AUTOSAR XML (schema 00050)
package /Pkg_ErrorMgrAgg_1_0_QM/ComponentTypes
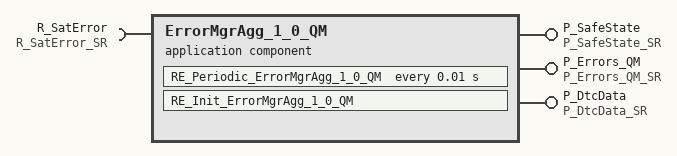
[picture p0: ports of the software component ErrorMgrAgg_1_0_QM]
  application sw component type ErrorMgrAgg_1_0_QM
    provide port P_SafeState: nonqueued-sender-com-spec{data-element=SafeStateOp, init-value=constant-reference=init_SafeStateOp}, provided-interface=P_SafeState_SR
    provide port P_Errors_QM: nonqueued-sender-com-spec=Errors_QM, provided-interface=P_Errors_QM_SR
    require port R_SatError: required-interface=R_SatError_SR
      required-com-specs:
        data-element=Data_ErrorMgr_ErrorCommPack_1_0_QM, init-value=constant-reference=init_Data_ErrorMgr_ErrorCommPack_1_0_QM
        data-element=Data_ErrorMgr_ErrorCommPack_2_0_QM, init-value=constant-reference=init_Data_ErrorMgr_ErrorCommPack_2_0_QM
        data-element=Data_ErrorMgr_ErrorCommPack_2_1_QM, init-value=constant-reference=init_Data_ErrorMgr_ErrorCommPack_2_1_QM
        data-element=Data_ErrorMgr_ErrorCommPack_QNX_QM, init-value=constant-reference=init_Data_ErrorMgr_ErrorCommPack_QNX_QM
    provide port P_DtcData: provided-interface=P_DtcData_SR
      provided-com-specs:
        data-element=Data_DtcStatus_QM, init-value=constant-reference=init_Data_DtcStatus_QM
        data-element=Data_DtcAddData_QM, init-value=constant-reference=init_Data_DtcAddData_QM
    behavior ErrorMgrAgg_1_0_QM_InternalBehavior: handle-termination-and-restart=NO-SUPPORT
      timing event TMT_RE_Periodic_ErrorMgrAgg_1_0_QM: start-on-event=RE_Periodic_ErrorMgrAgg_1_0_QM, period=0.01
      init event InitEvent: start-on-event=RE_Init_ErrorMgrAgg_1_0_QM
      port-api-options:
        enable-take-address=false, indirect-api=false, port=P_Errors_QM
        enable-take-address=false, indirect-api=false, port=P_SafeState
        enable-take-address=false, indirect-api=false, port=R_SatError
        enable-take-address=false, indirect-api=false, port=P_DtcData
      runnable RE_Periodic_ErrorMgrAgg_1_0_QM  # Periodic Runnable of Satellite
        data-receive-point-by-arguments:
          4 x access:
            REC_R_SatError_Data_ErrorMgr_ErrorCommPack_1_0_QM: accessed-variable=R_SatError.Data_ErrorMgr_ErrorCommPack_1_0_QM
            REC_R_SatError_Data_ErrorMgr_ErrorCommPack_2_0_QM: accessed-variable=R_SatError.Data_ErrorMgr_ErrorCommPack_2_0_QM
            REC_R_SatError_Data_ErrorMgr_ErrorCommPack_2_1_QM: accessed-variable=R_SatError.Data_ErrorMgr_ErrorCommPack_2_1_QM
            REC_R_SatError_Data_ErrorMgr_ErrorCommPack_QNX_QM: accessed-variable=R_SatError.Data_ErrorMgr_ErrorCommPack_QNX_QM
        data-send-points:
          4 x access:
            SEND_P_SafeState_SafeStateOp: accessed-variable=P_SafeState.SafeStateOp
            SEND_P_Errors_QM_Errors_QM: accessed-variable=P_Errors_QM.Errors_QM
            SEND_P_DtcData_Data_DtcStatus_QM: accessed-variable=P_DtcData.Data_DtcStatus_QM
            SEND_P_DtcData_Data_DtcAddData_QM: accessed-variable=P_DtcData.Data_DtcAddData_QM
      runnable RE_Init_ErrorMgrAgg_1_0_QM  # Init Runnable
  swc implementation ErrorMgrAgg_1_0_QM_Implementation: programming-language=C, vendor-id=0, behavior=ErrorMgrAgg_1_0_QM_InternalBehavior
    code-descriptors:
      code Default: artifact-descriptors=autosar-engineering-object=category=SWSRC
